VERSION ""

NS_ :

BS_: 500

BU_: Vector__XXX

BO_ 497 MSG_1F1: 8 Vector__XXX
 SG_ Wheel_Speed_FL_kph : 16|12@1+ (1,0) [0|255] "km/h" Vector__XXX
 SG_ Wheel_Speed_FL_mph : 16|12@1+ (0.621,0) [0|158.355] "mph" Vector__XXX
 SG_ Wheel_Speed_FR_kph : 28|12@1+ (1,0) [0|255] "km/h" Vector__XXX
 SG_ Wheel_Speed_FR_mph : 28|12@1+ (0.621,0) [0|158.355] "mph" Vector__XXX
 SG_ Wheel_Speed_RL_kph : 40|12@1+ (1,0) [0|255] "km/h" Vector__XXX
 SG_ Wheel_Speed_RL_mph : 40|12@1+ (0.621,0) [0|158.355] "mph" Vector__XXX
 SG_ Wheel_Speed_RR_kph : 52|12@1+ (1,0) [0|255] "km/h" Vector__XXX
 SG_ Wheel_Speed_RR_mph : 52|12@1+ (0.621,0) [0|158.355] "mph" Vector__XXX

BO_ 688 MSG_2B0: 5 Vector__XXX
 SG_ Steering_Angle : 0|16@1- (-0.1,0) [-900|900] "��" Vector__XXX

BO_ 790 MSG_316: 8 Vector__XXX
 SG_ Engine_Speed : 16|16@1+ (0.25,0) [0|10000] "rpm" Vector__XXX

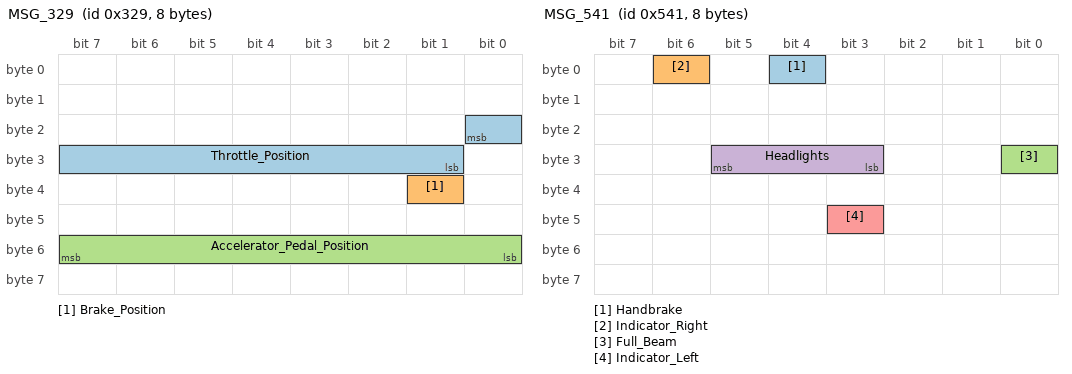
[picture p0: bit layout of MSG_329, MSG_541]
BO_ 809 MSG_329: 8 Vector__XXX
 SG_ Throttle_Position : 16|8@0+ (0.46948356808,-15.023474178) [0|0] "" Vector__XXX
 SG_ Brake_Position : 33|1@1+ (1,0) [0|1] "on/off" Vector__XXX
 SG_ Accelerator_Pedal_Position : 48|8@1+ (0.39063,0) [0|100] "%" Vector__XXX

BO_ 902 MSG_386: 8 Vector__XXX
 SG_ Wheel_Speed_FL_kph : 0|14@1+ (0.03,0) [0|300] "km/h" Vector__XXX
 SG_ Wheel_Speed_FL_mph : 0|14@1+ (0.01863,0) [0|186.3] "mph" Vector__XXX

BO_ 1087 MSG_43F: 8 Vector__XXX
 SG_ Gear : 56|3@0+ (1,0) [0|7] "" Vector__XXX

BO_ 1345 MSG_541: 8 Vector__XXX
 SG_ Handbrake : 4|1@0+ (1,0) [0|1] "on/off" Vector__XXX
 SG_ Indicator_Right : 6|1@0+ (1,0) [0|1] "on/off" Vector__XXX
 SG_ Full_Beam : 24|1@0+ (1,0) [0|1] "on/off" Vector__XXX
 SG_ Headlights : 29|3@0+ (1,0) [0|7] "on/off" Vector__XXX
 SG_ Indicator_Left : 43|1@0+ (1,0) [0|1] "on/off" Vector__XXX

BO_ 1349 MSG_545: 8 Vector__XXX
 SG_ Battery_Voltage : 32|8@0+ (0.1,0) [0|0] "V" Vector__XXX
